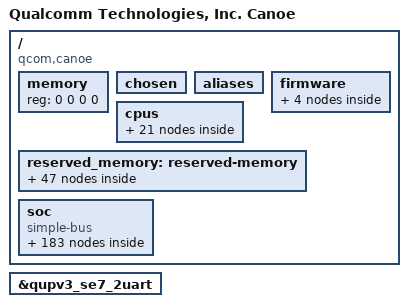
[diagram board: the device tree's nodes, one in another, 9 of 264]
// SPDX-License-Identifier: BSD-3-Clause
/*
 * Copyright (c) 2024 Qualcomm Innovation Center, Inc. All rights reserved.
 */

#include <dt-bindings/clock/qcom,rpmh.h>
#include <dt-bindings/clock/qcom,cambistmclkcc-canoe.h>
#include <dt-bindings/clock/qcom,camcc-canoe.h>
#include <dt-bindings/clock/qcom,evacc-canoe.h>
#include <dt-bindings/clock/qcom,gcc-canoe.h>
#include <dt-bindings/clock/qcom,gpucc-canoe.h>
#include <dt-bindings/clock/qcom,tcsrcc-canoe.h>
#include <dt-bindings/clock/qcom,videocc-canoe.h>
#include <dt-bindings/interrupt-controller/arm-gic.h>
#include <dt-bindings/interconnect/qcom,canoe.h>
#include <dt-bindings/interconnect/qcom,icc.h>
#include <dt-bindings/regulator/qcom,rpmh-regulator-levels.h>
#include <dt-bindings/soc/qcom,rpmh-rsc.h>
#include <dt-bindings/soc/qcom,ipcc.h>
#include <dt-bindings/spmi/spmi.h>
#include <dt-bindings/mailbox/qcom-ipcc-canoe.h>

/ {
	model = "Qualcomm Technologies, Inc. Canoe";
	compatible = "qcom,canoe";
	qcom,msm-id = <0x10294 0x10000>;
	interrupt-parent = <&intc>;

	#address-cells = <2>;
	#size-cells = <2>;
	memory { device_type = "memory"; reg = <0 0 0 0>; };


	chosen: chosen {
		bootargs = "nokaslr kpti=0 log_buf_len=256K swiotlb=0 loop.max_part=7";
		stdout-path = "/soc/qcom,qupv3_1_geni_se@ac0000/qcom,qup_uart@a9c000:115200n8";
	};

	aliases {
		serial0 = &qupv3_se7_2uart;
		hsuart0 = &qupv3_se18_4uart;
		ufshc1 = &ufshc_mem; /* Embedded UFS Slot */
		i2c0 = &qupv3_se0_i2c;
		i2c1 = &qupv3_se1_i2c;
		i2c2 = &qupv3_se2_i2c;
		i2c3 = &qupv3_se3_i2c;
		i2c4 = &qupv3_se4_i2c;
		i2c5 = &qupv3_se5_i2c;
		i2c6 = &qupv3_se6_i2c;
		i2c8 = &qupv3_se8_i2c;
		i2c9 = &qupv3_se9_i2c;
		i2c10 = &qupv3_se10_i2c;
		i2c11 = &qupv3_se11_i2c;
		i2c12 = &qupv3_se12_i2c;
		i2c13 = &qupv3_se13_i2c;
		i2c14 = &qupv3_se14_i2c;
		i2c15 = &qupv3_se15_i2c;
		i2c16 = &qupv3_se16_i2c;
		i2c17 = &qupv3_se17_i2c;
		i2c19 = &qupv3_se19_i2c;
		i2c20 = &qupv3_se20_i2c;
		i2c21 = &qupv3_se21_i2c;
		i2c22 = &qupv3_se22_i2c;
		i2c23 = &qupv3_se23_i2c;
		spi0 = &qupv3_se0_spi;
		spi1 = &qupv3_se1_spi;
		spi2 = &qupv3_se2_spi;
		spi3 = &qupv3_se3_spi;
		spi4 = &qupv3_se4_spi;
		spi5 = &qupv3_se5_spi;
		spi6 = &qupv3_se6_spi;
		spi8 = &qupv3_se8_spi;
		spi9 = &qupv3_se9_spi;
		spi10 = &qupv3_se10_spi;
		spi11 = &qupv3_se11_spi;
		spi14 = &qupv3_se14_spi;
		spi15 = &qupv3_se15_spi;
		spi16 = &qupv3_se16_spi;
		spi17 = &qupv3_se17_spi;
		spi19 = &qupv3_se19_spi;
		spi20 = &qupv3_se20_spi;
		spi21 = &qupv3_se21_spi;
	};

	firmware: firmware {
		qcom_scm: qcom_scm { };
	};

	cpus {
		#address-cells = <2>;
		#size-cells = <0>;

		CPU0: cpu@0 {
			device_type = "cpu";
			compatible = "arm,armv8";
			reg = <0x0 0x0>;
			enable-method = "psci";
			next-level-cache = <&L2_0>;
			L2_0: l2-cache {
			      compatible = "cache";
			      cache-level = <2>;
			};
		};

		CPU1: cpu@100 {
			device_type = "cpu";
			compatible = "arm,armv8";
			reg = <0x0 0x100>;
			enable-method = "psci";
			next-level-cache = <&L2_0>;
		};

		CPU2: cpu@200 {
			device_type = "cpu";
			compatible = "arm,armv8";
			reg = <0x0 0x200>;
			enable-method = "psci";
			next-level-cache = <&L2_0>;
		};

		CPU3: cpu@300 {
			device_type = "cpu";
			compatible = "arm,armv8";
			reg = <0x0 0x300>;
			enable-method = "psci";
			next-level-cache = <&L2_0>;
		};

		CPU4: cpu@400 {
			device_type = "cpu";
			compatible = "arm,armv8";
			reg = <0x0 0x400>;
			enable-method = "psci";
			next-level-cache = <&L2_0>;
		};

		CPU5: cpu@500 {
			device_type = "cpu";
			compatible = "arm,armv8";
			reg = <0x0 0x500>;
			enable-method = "psci";
			next-level-cache = <&L2_0>;
		};

		CPU6: cpu@10000 {
			device_type = "cpu";
			compatible = "arm,armv8";
			reg = <0x0 0x10000>;
			enable-method = "psci";
			next-level-cache = <&L2_6>;
			L2_6: l2-cache {
			      compatible = "cache";
			      cache-level = <2>;
			};
		};

		CPU7: cpu@10100 {
			device_type = "cpu";
			compatible = "arm,armv8";
			reg = <0x0 0x10100>;
			enable-method = "psci";
			next-level-cache = <&L2_6>;
		};

		cpu-map {
			cluster0 {
				core0 {
					cpu = <&CPU0>;
				};

				core1 {
					cpu = <&CPU1>;
				};

				core2 {
					cpu = <&CPU2>;
				};

				core3 {
					cpu = <&CPU3>;
				};

				core4 {
					cpu = <&CPU4>;
				};

				core5 {
					cpu = <&CPU5>;
				};
			};

			cluster1 {
				core0 {
					cpu = <&CPU6>;
				};

				core1 {
					cpu = <&CPU7>;
				};
			};
		};
	};

	reserved_memory: reserved-memory { };

	soc: soc { };
};

&firmware {
	qcom_scm {
		compatible = "qcom,scm";
		qcom,dload-mode = <&tcsr 0x19000>;
	};

	qcom_smcinvoke {
		compatible = "qcom,smcinvoke";
	};

	qcom_mem_object {
		compatible = "qcom,mem-object";
	};

	qtee_shmbridge {
		compatible = "qcom,tee-shared-memory-bridge";
	};
};

&soc {
	#address-cells = <2>;
	#size-cells = <2>;
	ranges = <0 0 0 0 0x10 0>;
	compatible = "simple-bus";

	ipcc_mproc: qcom,ipcc@1106000 {
		compatible = "qcom,ipcc";
		reg = <0x0 0x1106000 0x0 0x1000>;
		interrupts = <GIC_SPI 246 IRQ_TYPE_LEVEL_HIGH>;
		interrupt-controller;
		#interrupt-cells = <3>;
		#mbox-cells = <2>;
	};

	pdc: interrupt-controller@b220000 {
		compatible = "qcom,canoe-pdc", "qcom,pdc";
		reg = <0x0 0xb220000 0x0 0x10000>, <0x0 0x179600f0 0x0 0xf4>;
		qcom,pdc-ranges = <0 745 38>, <40 785 11>, <51 527 4>,
				  <58 534 2>, <61 537 20>, <84 559 14>,
				  <98 609 32>, <130 717 12>, <142 251 5>,
				  <147 796 16>, <163 783 2>, <165 531 2>,
				  <167 536 1>, <168 557 2>, <170 415 1>,
				  <171 438 1>, <172 579 1>, <173 703 1>,
				  <174 708 1>, <175 714 1>, <176 68 1>,
				  <177 86 1>, <178 96 1>, <179 249 1>;
		#interrupt-cells = <2>;
		interrupt-parent = <&intc>;
		interrupt-controller;
	};

	tcsr_mutex_block: syscon@1f40000 {
		compatible = "syscon";
		reg = <0x0 0x1f40000 0x0 0x20000>;
	};

	tcsr: syscon@1fc0000 {
		compatible = "syscon";
		reg = <0x0 0x1fc0000 0x0 0x30000>;
	};

	tcsr_mutex: hwlock {
		compatible = "qcom,tcsr-mutex";
		syscon = <&tcsr_mutex_block 0 0x1000>;
		#hwlock-cells = <1>;
	};

	aoss_qmp: power-controller@c300000 {
		compatible = "qcom,aoss-qmp";
		reg = <0x0 0xc300000 0x0 0x400>;
		interrupt-parent = <&ipcc_mproc>;
		interrupts = <IPCC_MPROC_AOP
			      IPCC_MPROC_SIGNAL_GLINK_QMP
			      IRQ_TYPE_EDGE_RISING>;
		mboxes = <&ipcc_mproc IPCC_MPROC_AOP
			  IPCC_MPROC_SIGNAL_GLINK_QMP>;

		#power-domain-cells = <1>;
		#clock-cells = <0>;
	};

	qmp_tme: qcom,qmp-tme {
		compatible = "qcom,qmp-mbox";
		qcom,remote-pid = <14>;
		mboxes = <&ipcc_mproc IPCC_MPROC_TME
			  IPCC_MPROC_SIGNAL_GLINK_QMP>;
		mbox-names = "tme_qmp";
		interrupt-parent = <&ipcc_mproc>;
		interrupts = <IPCC_MPROC_TME
			      IPCC_MPROC_SIGNAL_GLINK_QMP
			      IRQ_TYPE_EDGE_RISING>;

		label = "tme";
		qcom,early-boot;
		priority = <0>;
		mbox-desc-offset = <0x0>;
		#mbox-cells = <1>;
	};

	qcom,smp2p-adsp {
		compatible = "qcom,smp2p";
		qcom,smem = <443>, <429>;
		interrupt-parent = <&ipcc_mproc>;
		interrupts = <IPCC_MPROC_LPASS IPCC_MPROC_SIGNAL_SMP2P
			      IRQ_TYPE_EDGE_RISING>;
		mboxes = <&ipcc_mproc IPCC_MPROC_LPASS
			  IPCC_MPROC_SIGNAL_SMP2P>;
		qcom,local-pid = <0>;
		qcom,remote-pid = <2>;

		adsp_smp2p_out: master-kernel {
			qcom,entry-name = "master-kernel";
			#qcom,smem-state-cells = <1>;
		};

		adsp_smp2p_in: slave-kernel {
			qcom,entry-name = "slave-kernel";
			interrupt-controller;
			#interrupt-cells = <2>;
		};

		sleepstate_smp2p_out: sleepstate-out {
			qcom,entry-name = "sleepstate";
			#qcom,smem-state-cells = <1>;
		};

		sleepstate_smp2p_in: qcom,sleepstate-in {
			qcom,entry-name = "sleepstate_see";
			interrupt-controller;
			#interrupt-cells = <2>;
		};

		smp2p_rdbg2_out: qcom,smp2p-rdbg2-out {
			qcom,entry-name = "rdbg";
			#qcom,smem-state-cells = <1>;
		};

		smp2p_rdbg2_in: qcom,smp2p-rdbg2-in {
			qcom,entry-name = "rdbg";
			interrupt-controller;
			#interrupt-cells = <2>;
		};
	};

	qcom,smp2p-cdsp {
		compatible = "qcom,smp2p";
		qcom,smem = <94>, <432>;
		interrupt-parent = <&ipcc_mproc>;
		interrupts = <IPCC_MPROC_CDSP IPCC_MPROC_SIGNAL_SMP2P
			      IRQ_TYPE_EDGE_RISING>;
		mboxes = <&ipcc_mproc IPCC_MPROC_CDSP IPCC_MPROC_SIGNAL_SMP2P>;
		qcom,local-pid = <0>;
		qcom,remote-pid = <5>;

		cdsp_smp2p_out: master-kernel {
			qcom,entry-name = "master-kernel";
			#qcom,smem-state-cells = <1>;
		};

		cdsp_smp2p_in: slave-kernel {
			qcom,entry-name = "slave-kernel";
			interrupt-controller;
			#interrupt-cells = <2>;
		};

		smp2p_rdbg5_out: qcom,smp2p-rdbg5-out {
			qcom,entry-name = "rdbg";
			#qcom,smem-state-cells = <1>;
		};

		smp2p_rdbg5_in: qcom,smp2p-rdbg5-in {
			qcom,entry-name = "rdbg";
			interrupt-controller;
			#interrupt-cells = <2>;
		};
	};

	qcom,smp2p-modem {
		compatible = "qcom,smp2p";
		qcom,smem = <435>, <428>;
		interrupt-parent = <&ipcc_mproc>;
		interrupts = <IPCC_MPROC_MPSS IPCC_MPROC_SIGNAL_SMP2P
			      IRQ_TYPE_EDGE_RISING>;
		mboxes = <&ipcc_mproc IPCC_MPROC_MPSS IPCC_MPROC_SIGNAL_SMP2P>;
		qcom,local-pid = <0>;
		qcom,remote-pid = <1>;

		modem_smp2p_out: master-kernel {
			qcom,entry-name = "master-kernel";
			#qcom,smem-state-cells = <1>;
		};

		modem_smp2p_in: slave-kernel {
			qcom,entry-name = "slave-kernel";
			interrupt-controller;
			#interrupt-cells = <2>;
		};

		smp2p_ipa_1_out: qcom,smp2p-ipa-1-out {
			qcom,entry-name = "ipa";
			#qcom,smem-state-cells = <1>;
		};

		/* ipa - inbound entry from mss */
		smp2p_ipa_1_in: qcom,smp2p-ipa-1-in {
			qcom,entry-name = "ipa";
			interrupt-controller;
			#interrupt-cells = <2>;
		};

		smp2p_smem_mailbox_1_out: qcom,smp2p-smem-mailbox-1-out {
			qcom,entry-name = "smem-mailbox";
			#qcom,smem-state-cells = <1>;
		};

		smp2p_smem_mailbox_1_in: qcom,smp2p-smem-mailbox-1-in {
			qcom,entry-name = "smem-mailbox";
			interrupt-controller;
			#interrupt-cells = <2>;
		};
	};

	qcom,smp2p-soccp {
		compatible = "qcom,smp2p";
		qcom,smem = <617>, <616>;
		interrupt-parent = <&ipcc_mproc>;
		interrupts = <IPCC_MPROC_SOCCP IPCC_MPROC_SIGNAL_SMP2P
			      IRQ_TYPE_EDGE_RISING>;
		mboxes = <&ipcc_mproc IPCC_MPROC_SOCCP IPCC_MPROC_SIGNAL_SMP2P>;
		qcom,local-pid = <0>;
		qcom,remote-pid = <19>;

		soccp_smp2p_out: master-kernel {
			qcom,entry-name = "master-kernel";
			#qcom,smem-state-cells = <1>;
		};

		soccp_smp2p_in: slave-kernel {
			qcom,entry-name = "slave-kernel";
			interrupt-controller;
			#interrupt-cells = <2>;
		};
	};

	qcom,smp2p_sleepstate {
		compatible = "qcom,smp2p-sleepstate";
		qcom,smem-states = <&sleepstate_smp2p_out 0>;
		interrupt-parent = <&sleepstate_smp2p_in>;
		interrupts = <0 0>;
		interrupt-names = "smp2p-sleepstate-in";
	};

	tlmm: pinctrl@f000000 {
		compatible = "qcom,canoe-tlmm";
		reg = <0x0 0xf000000 0x0 0x1000000>;
		interrupts = <GIC_SPI 208 IRQ_TYPE_LEVEL_HIGH>;
		gpio-controller;
		#gpio-cells = <2>;
		interrupt-controller;
		#interrupt-cells = <2>;
		wakeup-parent = <&pdc>;
	};

	slimbam: bamdma@6C04000 {
		compatible = "qcom,bam-v1.7.0";
		qcom,controlled-remotely;
		reg = <0x6C04000 0x20000>, <0x6C8F000 0x1000>;
		reg-names = "bam", "bam_remote_mem";
		num-channels  = <31>;
		interrupts = <0 164 IRQ_TYPE_LEVEL_HIGH>;
		#dma-cells = <1>;
		qcom,ee = <1>;
		qcom,num-ees = <2>;
	};

	slim_msm: slim@6C40000 {
		compatible = "qcom,slim-ngd-v1.5.0";
		reg = <0x6C40000 0x2C000>, <0x6C8E000 0x1000>;
		reg-names = "ctrl", "slimbus_remote_mem";
		interrupts = <0 163 IRQ_TYPE_LEVEL_HIGH>;
		dmas = <&slimbam 3>, <&slimbam 4>;
		dma-names = "rx", "tx";
		#address-cells = <1>;
		#size-cells = <0>;
		status = "disabled";
	};

	intc: interrupt-controller@17000000 {
		compatible = "arm,gic-v3";
		#interrupt-cells = <3>;
		interrupt-controller;
		#redistributor-regions = <1>;
		redistributor-stride = <0x0 0x40000>;
		reg = <0x0 0x17000000 0x0 0x10000>,	/* GICD */
		      <0x0 0x17080000 0x0 0x200000>;	/* GICR * 8 */
		interrupts = <GIC_PPI 9 IRQ_TYPE_LEVEL_HIGH>;
	};

	memtimer: timer@17810000 {
		#address-cells = <1>;
		#size-cells = <1>;
		ranges;
		compatible = "arm,armv7-timer-mem";
		reg = <0x0 0x17810000 0x0 0x1000>;
		clock-frequency = <19200000>;

		frame@17811000 {
			frame-number = <0>;
			interrupts = <GIC_SPI 8 IRQ_TYPE_LEVEL_HIGH>,
				     <GIC_SPI 6 IRQ_TYPE_LEVEL_HIGH>;
			reg = <0x17811000 0x1000>,
			      <0x17812000 0x1000>;
		};

		frame@17813000 {
			frame-number = <1>;
			interrupts = <GIC_SPI 9 IRQ_TYPE_LEVEL_HIGH>;
			reg = <0x17813000 0x1000>;
			status = "disabled";
		};

		frame@17815000 {
			frame-number = <2>;
			interrupts = <GIC_SPI 10 IRQ_TYPE_LEVEL_HIGH>;
			reg = <0x17815000 0x1000>;
			status = "disabled";
		};

		frame@17817000 {
			frame-number = <3>;
			interrupts = <GIC_SPI 11 IRQ_TYPE_LEVEL_HIGH>;
			reg = <0x17817000 0x1000>;
			status = "disabled";
		};

		frame@17819000 {
			frame-number = <4>;
			interrupts = <GIC_SPI 12 IRQ_TYPE_LEVEL_HIGH>;
			reg = <0x17819000 0x1000>;
			status = "disabled";
		};

		frame@1781b000 {
			frame-number = <5>;
			interrupts = <GIC_SPI 13 IRQ_TYPE_LEVEL_HIGH>;
			reg = <0x1781b000 0x1000>;
			status = "disabled";
		};

		frame@1781d000 {
			frame-number = <6>;
			interrupts = <GIC_SPI 14 IRQ_TYPE_LEVEL_HIGH>;
			reg = <0x1781d000 0x1000>;
			status = "disabled";
		};
	};

	qcom_tzlog: tz-log@0 {
	};

	eud: qcom,msm-eud@88e0000 {
		compatible = "qcom,msm-eud";
		interrupt-names = "eud_irq";
		interrupt-parent = <&pdc>;
		interrupts = <11 IRQ_TYPE_LEVEL_HIGH>;
		reg = <0x0 0x88e0000 0x0 0x2000>,
				<0x0 0x88e2000 0x0 0x1000>;
		reg-names = "eud_base", "eud_mode_mgr2";
		qcom,secure-eud-en;
		qcom,eud-utmi-delay = /bits/ 16 <255>;
		status = "disabled";
	};

	cache-controller@31800000 {
		compatible = "qcom,canoe-llcc";
		reg = <0x0 0x31800000 0x0 0x200000>, <0x0 0x32800000 0x0 0x200000>,
			<0x0 0x31C00000 0x0 0x200000>, <0x0 0x32C00000 0x0 0x200000>,
			<0x0 0x34800000 0x0 0x200000>, <0x0 0x34C00000 0x0 0x200000>;
		reg-names = "llcc0_base", "llcc1_base", "llcc2_base",
			"llcc3_base", "llcc_broadcast_or_base",
			"llcc_broadcast_and_base";
		interrupts = <GIC_SPI 266 IRQ_TYPE_LEVEL_HIGH>;
		cap-based-alloc-and-pwr-collapse;
	};

	arch_timer: timer {
		compatible = "arm,armv8-timer";
		interrupts = <GIC_PPI 13 (GIC_CPU_MASK_SIMPLE(8) | IRQ_TYPE_LEVEL_LOW)>,
			     <GIC_PPI 14 (GIC_CPU_MASK_SIMPLE(8) | IRQ_TYPE_LEVEL_LOW)>,
			     <GIC_PPI 11 (GIC_CPU_MASK_SIMPLE(8) | IRQ_TYPE_LEVEL_LOW)>,
			     <GIC_PPI 10 (GIC_CPU_MASK_SIMPLE(8) | IRQ_TYPE_LEVEL_LOW)>;
		clock-frequency = <19200000>;
	};

	apps_rsc: rsc@18900000 {
		label = "apps_rsc";
		compatible = "qcom,rpmh-rsc";
		reg = <0x0 0x18900000 0x0 0x10000>,
		      <0x0 0x18910000 0x0 0x10000>,
		      <0x0 0x18920000 0x0 0x10000>;
		reg-names = "drv-0", "drv-1", "drv-2";
		qcom,drv-count = <3>;
		interrupts = <GIC_SPI 3 IRQ_TYPE_LEVEL_HIGH>,
			     <GIC_SPI 4 IRQ_TYPE_LEVEL_HIGH>,
			     <GIC_SPI 5 IRQ_TYPE_LEVEL_HIGH>;

		apps_rsc_drv2: drv@2 {
			qcom,drv-id = <2>;
			qcom,tcs-offset = <0xd00>;
			qcom,tcs-distance = <0x2a0>;
			channel@0 {
				qcom,tcs-config = <ACTIVE_TCS    3>,
						  <SLEEP_TCS     2>,
						  <WAKE_TCS      2>,
						  <CONTROL_TCS   0>,
						  <FAST_PATH_TCS 1>;
			};
		};
	};

	cam_rsc: rsc@9545000 {
		label = "cam_rsc";
		compatible = "qcom,rpmh-rsc";
		reg = <0x0 0x9545000 0x0 0x1000>,
		      <0x0 0x9546000 0x0 0x1000>,
		      <0x0 0x9547000 0x0 0x1000>;
		reg-names = "drv-0", "drv-1", "drv-2";
		qcom,drv-count = <3>;
		qcom,hw-channel;
		interrupts = <GIC_SPI 368 IRQ_TYPE_LEVEL_HIGH>,
			     <GIC_SPI 369 IRQ_TYPE_LEVEL_HIGH>,
			     <GIC_SPI 370 IRQ_TYPE_LEVEL_HIGH>;
		clocks = <&camcc CAM_CC_DRV_AHB_CLK>;

		cam_rsc_drv0: drv@0 {
			qcom,drv-id = <0>;
			qcom,tcs-offset = <0x520>;
			qcom,tcs-distance = <0x150>;
			channel@0 {
				qcom,tcs-config = <ACTIVE_TCS    0>,
						  <WAKE_TCS      1>,
						  <SLEEP_TCS     1>,
						  <CONTROL_TCS   0>,
						  <FAST_PATH_TCS 0>;
			};

			channel@1 {
				qcom,tcs-config = <ACTIVE_TCS    0>,
						  <WAKE_TCS      1>,
						  <SLEEP_TCS     1>,
						  <CONTROL_TCS   0>,
						  <FAST_PATH_TCS 0>;
			};
		};

		cam_rsc_drv1: drv@1 {
			qcom,drv-id = <1>;
			qcom,tcs-offset = <0x520>;
			qcom,tcs-distance = <0x150>;
			channel@0 {
				qcom,tcs-config = <ACTIVE_TCS    0>,
						  <WAKE_TCS      1>,
						  <SLEEP_TCS     1>,
						  <CONTROL_TCS   0>,
						  <FAST_PATH_TCS 0>;
			};

			channel@1 {
				qcom,tcs-config = <ACTIVE_TCS    0>,
						  <WAKE_TCS      1>,
						  <SLEEP_TCS     1>,
						  <CONTROL_TCS   0>,
						  <FAST_PATH_TCS 0>;
			};
		};

		cam_rsc_drv2: drv@2 {
			qcom,drv-id = <2>;
			qcom,tcs-offset = <0x520>;
			qcom,tcs-distance = <0x150>;
			channel@0 {
				qcom,tcs-config = <ACTIVE_TCS    0>,
						  <WAKE_TCS      1>,
						  <SLEEP_TCS     1>,
						  <CONTROL_TCS   0>,
						  <FAST_PATH_TCS 0>;
			};

			channel@1 {
				qcom,tcs-config = <ACTIVE_TCS    0>,
						  <WAKE_TCS      1>,
						  <SLEEP_TCS     1>,
						  <CONTROL_TCS   0>,
						  <FAST_PATH_TCS 0>;
			};
		};
	};

	disp_crm: crm@9bc3000 {
		label = "disp_crm";
		compatible = "qcom,disp-crm-v3";
		reg = <0x0 0x9bc3000 0x0 0x9000>, <0x0 0x9bcc000 0x0 0x400>, <0x0 0x9bcc400 0x0 0x400>,
		      <0x0 0x9bcc800 0x0 0x2000>, <0x0 0x9bce800 0x0 0x600>, <0x0 0x9bcee00 0x0 0x200>;
		reg-names = "base", "crm_b", "crm_b_pt", "crm_c", "crm_v", "common";
		interrupts = <GIC_SPI 812 IRQ_TYPE_EDGE_RISING>,
			     <GIC_SPI 813 IRQ_TYPE_EDGE_RISING>,
			     <GIC_SPI 814 IRQ_TYPE_EDGE_RISING>,
			     <GIC_SPI 815 IRQ_TYPE_EDGE_RISING>,
			     <GIC_SPI 816 IRQ_TYPE_EDGE_RISING>,
			     <GIC_SPI 817 IRQ_TYPE_EDGE_RISING>;
		interrupt-names = "disp_crm_drv0",
				  "disp_crm_drv1",
				  "disp_crm_drv2",
				  "disp_crm_drv3",
				  "disp_crm_drv4",
				  "disp_crm_drv5";
		qcom,hw-drv-ids = <0 1 2 3 4 5>;
		qcom,sw-drv-ids = <0 1 2 3 4 5>;
	};

	cam_crm: crm@9548000 {
		label = "cam_crm";
		compatible = "qcom,cam-crm-v3";
		reg = <0x0 0x9548000 0x0 0x1e00>, <0x0 0x9549e00 0x0 0x400>, <0x0 0x954a200 0x0 0x400>,
		      <0x0 0x954a600 0x0 0x2000>, <0x0 0x954c600 0x0 0x600>, <0x0 0x954cc00 0x0 0x200>;
		reg-names = "base", "crm_b", "crm_b_pt", "crm_c", "crm_v", "common";
		interrupts = <GIC_SPI 121 IRQ_TYPE_EDGE_RISING>;
		interrupt-names = "cam_crm_drv0";
		clocks = <&camcc CAM_CC_DRV_AHB_CLK>;
		qcom,hw-drv-ids = <0 1 2>;
		qcom,sw-drv-ids = <0>;
	};

	pcie_crm: crm@1d01000 {
		label = "pcie_crm";
		compatible = "qcom,pcie-crm-v3";
		reg = <0x0 0x1d01000 0x0 0x2000>, <0x0 0x1d03000 0x0 0x400>, <0x0 0x1d03400 0x0 0x400>,
		      <0x0 0x1d03800 0x0 0x2000>, <0x0 0x1d05800 0x0 0x600>, <0x0 0x1d05e00 0x0 0x200>;
		reg-names = "base", "crm_b", "crm_b_pt", "crm_c", "crm_v", "common";
		interrupts = <GIC_SPI 641 IRQ_TYPE_EDGE_RISING>;
		interrupt-names = "pcie_crm_drv0";
		clocks = <&pcie_0_pipe_clk>;
		qcom,hw-drv-ids = <0 1>;
		qcom,sw-drv-ids = <0>;
	};

	pcie_pdc: pdc@b370000 {
		compatible = "qcom,canoe-pcie-pdc", "qcom,pcie-pdc";
		reg = <0x0 0xb370000 0x0 0x10000>;
	};

	qcom,msm-imem@14680000 {
		compatible = "qcom,msm-imem";
		reg = <0x14680000 0x1000>;
		ranges = <0x0 0x14680000 0x1000>;
		#address-cells = <1>;
		#size-cells = <1>;

		mem_dump_table@10 {
			compatible = "qcom,msm-imem-mem_dump_table";
			reg = <0x10 0x8>;
		};

		restart_reason@65c {
			compatible = "qcom,msm-imem-restart_reason";
			reg = <0x65c 0x4>;
		};

		dload_type@1c {
			compatible = "qcom,msm-imem-dload-type";
			reg = <0x1c 0x4>;
		};

		boot_stats@6b0 {
			compatible = "qcom,msm-imem-boot_stats";
			reg = <0x6b0 0x20>;
		};

		kaslr_offset@6d0 {
			compatible = "qcom,msm-imem-kaslr_offset";
			reg = <0x6d0 0xc>;
		};

		pil@94c {
			compatible = "qcom,pil-reloc-info";
			reg = <0x94c 0xc8>;
		};

		pil@6dc {
			compatible = "qcom,msm-imem-pil-disable-timeout";
			reg = <0x6dc 0x4>;
		};

		diag_dload@c8 {
			compatible = "qcom,msm-imem-diag-dload";
			reg = <0xc8 0xc8>;
		};

		modem_dsm@c98 {
			compatible = "qcom,msm-imem-mss-dsm";
			reg = <0xc98 0x10>;
		};

		sys_dbg@af8 {
			compatible = "qcom,msm-imem-gpu-dump-skip";
			reg = <0xb0c 0x4>;
		};
	};

	clocks {
		xo_board: xo_board {
			compatible = "fixed-clock";
			clock-frequency = <76800000>;
			clock-output-names = "xo_board";
			#clock-cells = <0>;
		};

		sleep_clk: sleep_clk {
			compatible = "fixed-clock";
			clock-frequency = <32000>;
			clock-output-names = "sleep_clk";
			#clock-cells = <0>;
		};

		pcie_0_pipe_clk: pcie_0_pipe_clk {
			compatible = "fixed-clock";
			clock-frequency = <1000>;
			clock-output-names = "pcie_0_pipe_clk";
			#clock-cells = <0>;
		};

		ufs_phy_rx_symbol_0_clk: ufs_phy_rx_symbol_0_clk {
			compatible = "fixed-clock";
			clock-frequency = <1000>;
			clock-output-names = "ufs_phy_rx_symbol_0_clk";
			#clock-cells = <0>;
		};

		ufs_phy_rx_symbol_1_clk: ufs_phy_rx_symbol_1_clk {
			compatible = "fixed-clock";
			clock-frequency = <1000>;
			clock-output-names = "ufs_phy_rx_symbol_1_clk";
			#clock-cells = <0>;
		};

		ufs_phy_tx_symbol_0_clk: ufs_phy_tx_symbol_0_clk {
			compatible = "fixed-clock";
			clock-frequency = <1000>;
			clock-output-names = "ufs_phy_tx_symbol_0_clk";
			#clock-cells = <0>;
		};

		usb3_phy_wrapper_gcc_usb30_pipe_clk: usb3_phy_wrapper_gcc_usb30_pipe_clk {
			compatible = "fixed-clock";
			clock-frequency = <1000>;
			clock-output-names = "usb3_phy_wrapper_gcc_usb30_pipe_clk";
			#clock-cells = <0>;
		};
	};

	cxo: bi_tcxo {
		compatible = "fixed-factor-clock";
		clocks = <&xo_board>;
		clock-mult = <1>;
		clock-div = <4>;
		#clock-cells = <0>;
		clock-output-names = "bi_tcxo";
	};

	cxo_a: bi_tcxo_ao {
		compatible = "fixed-factor-clock";
		clocks = <&xo_board>;
		clock-mult = <1>;
		clock-div = <4>;
		#clock-cells = <0>;
		clock-output-names = "bi_tcxo_ao";
	};

	rpmhcc: clock-controller {
		compatible = "fixed-clock";
		clock-output-names = "rpmh_clocks";
		clock-frequency = <19200000>;
		#clock-cells = <1>;
	};

	cambistmclkcc: clock-controller@1760000 {
		compatible = "qcom,dummycc";
		clock-output-names = "cambistmclkcc_clocks";
		#clock-cells = <1>;
		#reset-cells = <1>;
	};

	camcc_crm: syscon@954a600 {
		compatible = "syscon";
		reg = <0x0 0x954a600 0x0 0x2000>;
	};

	camcc: clock-controller@956d000 {
		compatible = "qcom,dummycc";
		clock-output-names = "camcc_clocks";
		#clock-cells = <1>;
		#reset-cells = <1>;
	};

	evacc: clock-controller@24f0000 {
		compatible = "qcom,dummycc";
		clock-output-names = "evacc_clocks";
		#clock-cells = <1>;
		#reset-cells = <1>;
	};


	gcc: clock-controller@100000 {
		compatible = "qcom,canoe-gcc", "syscon";
		reg = <0x0 0x100000 0x0 0x1f4200>;
		reg-name = "cc_base";
		vdd_cx-supply = <&VDD_CX_LEVEL>;
		vdd_mx-supply = <&VDD_MX_LEVEL>;
		clocks = <&rpmhcc RPMH_CXO_CLK>,
			 <&pcie_0_pipe_clk>,
			 <&sleep_clk>,
			 <&ufs_phy_rx_symbol_0_clk>,
			 <&ufs_phy_rx_symbol_1_clk>,
			 <&ufs_phy_tx_symbol_0_clk>,
			 <&usb3_phy_wrapper_gcc_usb30_pipe_clk>;
		clock-names = "bi_tcxo",
			      "pcie_0_pipe_clk",
			      "sleep_clk",
			      "ufs_phy_rx_symbol_0_clk",
			      "ufs_phy_rx_symbol_1_clk",
			      "ufs_phy_tx_symbol_0_clk",
			      "usb3_phy_wrapper_gcc_usb30_pipe_clk";
		#clock-cells = <1>;
		#reset-cells = <1>;
	};

	gpucc: clock-controller@3d90000 {
		compatible = "qcom,dummycc";
		clock-output-names = "gpucc_clocks";
		#clock-cells = <1>;
		#reset-cells = <1>;
	};

	tcsrcc: clock-controller@1fd5044 {
		compatible = "qcom,dummycc";
		clock-output-names = "tcsrcc_clocks";
		#clock-cells = <1>;
		#reset-cells = <1>;
	};

	videocc: clock-controller@20f0000 {
		compatible = "qcom,dummycc";
		clock-output-names = "videocc_clocks";
		#clock-cells = <1>;
		#reset-cells = <1>;
	};

	apsscc: syscon@17c00000 {
		compatible = "syscon";
		reg = <0x0 0x17c00000 0x0 0x2da3000>;
	};

	gxclkctl: syscon@3d64000 {
		compatible = "syscon";
		reg = <0x0 0x3d64000 0x0 0x5000>;
	};

	mccc: syscon@310ba000 {
		compatible = "syscon";
		reg = <0x0 0x310ba000 0x0 0x800>;
	};

	/* CAM_CC GDSCs */
	cam_cc_ipe_0_gdsc: qcom,gdsc@958d174 {
		compatible = "qcom,stub-regulator";
		regulator-name = "cam_cc_ipe_0_gdsc";
		qcom,support-hw-trigger;
		qcom,support-cfg-gdscr;
	};

	cam_cc_ofe_gdsc: qcom,gdsc@958d0c8 {
		compatible = "qcom,stub-regulator";
		regulator-name = "cam_cc_ofe_gdsc";
		qcom,support-hw-trigger;
		qcom,support-cfg-gdscr;
	};

	cam_cc_tfe_0_gdsc: qcom,gdsc@958e004 {
		compatible = "qcom,stub-regulator";
		regulator-name = "cam_cc_tfe_0_gdsc";
		qcom,support-cfg-gdscr;
	};

	cam_cc_tfe_1_gdsc: qcom,gdsc@958e080 {
		compatible = "qcom,stub-regulator";
		regulator-name = "cam_cc_tfe_1_gdsc";
		qcom,support-cfg-gdscr;
	};

	cam_cc_tfe_2_gdsc: qcom,gdsc@958e0e4 {
		compatible = "qcom,stub-regulator";
		regulator-name = "cam_cc_tfe_2_gdsc";
		qcom,support-cfg-gdscr;
	};

	cam_cc_titan_top_gdsc: qcom,gdsc@958e334 {
		compatible = "qcom,stub-regulator";
		regulator-name = "cam_cc_titan_top_gdsc";
		qcom,support-cfg-gdscr;
	};

	/* EVA_CC GDSCs */
	eva_cc_mvs0_gdsc: qcom,gdsc@24f8068 {
		compatible = "qcom,stub-regulator";
		regulator-name = "eva_cc_mvs0_gdsc";
		qcom,support-hw-trigger;
		qcom,support-cfg-gdscr;
	};

	eva_cc_mvs0c_gdsc: qcom,gdsc@24f8034 {
		compatible = "qcom,stub-regulator";
		regulator-name = "eva_cc_mvs0c_gdsc";
		qcom,support-cfg-gdscr;
	};

	gcc_apcs_gdsc_vote_ctrl: syscon@15214c {
		compatible = "syscon";
		reg = <0x0 0x15214c 0x0 0x4>;
	};

	/* GCC GDSCs */
	gcc_pcie_0_gdsc: qcom,gdsc@16b004 {
		compatible = "qcom,gdsc";
		reg = <0x0 0x16b004 0x0 0x4>;
		regulator-name = "gcc_pcie_0_gdsc";
		parent-supply = <&VDD_CX_LEVEL>;
		qcom,retain-regs;
		qcom,no-status-check-on-disable;
		qcom,collapse-vote = <&gcc_apcs_gdsc_vote_ctrl 0>;
		qcom,support-cfg-gdscr;
	};

	gcc_pcie_0_phy_gdsc: qcom,gdsc@16c000 {
		compatible = "qcom,gdsc";
		reg = <0x0 0x16c000 0x0 0x4>;
		regulator-name = "gcc_pcie_0_phy_gdsc";
		parent-supply = <&VDD_MX_LEVEL>;
		qcom,retain-regs;
		qcom,no-status-check-on-disable;
		qcom,collapse-vote = <&gcc_apcs_gdsc_vote_ctrl 2>;
		qcom,support-cfg-gdscr;
	};

	gcc_ufs_mem_phy_gdsc: qcom,gdsc@19e000 {
		compatible = "qcom,gdsc";
		reg = <0x0 0x19e000 0x0 0x4>;
		regulator-name = "gcc_ufs_mem_phy_gdsc";
		parent-supply = <&VDD_MX_LEVEL>;
		proxy-supply = <&gcc_ufs_mem_phy_gdsc>;
		qcom,proxy-consumer-enable;
		qcom,retain-regs;
		qcom,support-cfg-gdscr;
	};

	gcc_ufs_phy_gdsc: qcom,gdsc@177004 {
		compatible = "qcom,gdsc";
		reg = <0x0 0x177004 0x0 0x4>;
		regulator-name = "gcc_ufs_phy_gdsc";
		parent-supply = <&VDD_CX_LEVEL>;
		proxy-supply = <&gcc_ufs_phy_gdsc>;
		qcom,proxy-consumer-enable;
		qcom,retain-regs;
		qcom,support-cfg-gdscr;
	};

	gcc_usb30_prim_gdsc: qcom,gdsc@139004 {
		compatible = "qcom,gdsc";
		reg = <0x0 0x139004 0x0 0x4>;
		regulator-name = "gcc_usb30_prim_gdsc";
		proxy-supply = <&gcc_usb30_prim_gdsc>;
		qcom,proxy-consumer-enable;
		qcom,retain-regs;
		qcom,support-cfg-gdscr;
	};

	gcc_usb3_phy_gdsc: qcom,gdsc@150018 {
		compatible = "qcom,gdsc";
		reg = <0x0 0x150018 0x0 0x4>;
		regulator-name = "gcc_usb3_phy_gdsc";
		parent-supply = <&VDD_MX_LEVEL>;
		proxy-supply = <&gcc_usb3_phy_gdsc>;
		qcom,proxy-consumer-enable;
		qcom,retain-regs;
		qcom,support-cfg-gdscr;
	};

	/* GPU_CC GDSCs */
	gpu_cc_cx_gdsc_hw_ctrl: syscon@3d99094 {
		compatible = "syscon";
		reg = <0x0 0x3d99094 0x0 0x4>;
	};

	gpu_cc_cx_gdsc: qcom,gdsc@3d99080 {
		compatible = "qcom,stub-regulator";
		regulator-name = "gpu_cc_cx_gdsc";
		qcom,support-cfg-gdscr;
	};

	/* VIDEO_CC GDSCs */
	video_cc_mvs0_gdsc: qcom,gdsc@20f80a8 {
		compatible = "qcom,stub-regulator";
		regulator-name = "video_cc_mvs0_gdsc";
		qcom,support-hw-trigger;
		qcom,support-cfg-gdscr;
	};

	video_cc_mvs0_vpp0_gdsc: qcom,gdsc@20f8120 {
		compatible = "qcom,stub-regulator";
		regulator-name = "video_cc_mvs0_vpp0_gdsc";
		qcom,support-hw-trigger;
		qcom,support-cfg-gdscr;
	};

	video_cc_mvs0_vpp1_gdsc: qcom,gdsc@20f80f4 {
		compatible = "qcom,stub-regulator";
		regulator-name = "video_cc_mvs0_vpp1_gdsc";
		qcom,support-hw-trigger;
		qcom,support-cfg-gdscr;
	};

	video_cc_mvs0a_gdsc: qcom,gdsc@20f807c {
		compatible = "qcom,stub-regulator";
		regulator-name = "video_cc_mvs0a_gdsc";
		qcom,support-hw-trigger;
		qcom,support-cfg-gdscr;
	};

	video_cc_mvs0c_gdsc: qcom,gdsc@20f814c {
		compatible = "qcom,stub-regulator";
		regulator-name = "video_cc_mvs0c_gdsc";
		qcom,support-cfg-gdscr;
	};

	clk_virt: interconnect@0 {
		compatible = "qcom,canoe-clk_virt";
		qcom,stub;
		#interconnect-cells = <1>;
	};

	mc_virt: interconnect@1 {
		compatible = "qcom,canoe-mc_virt";
		qcom,stub;
		#interconnect-cells = <1>;
	};

	config_noc: interconnect@1600000 {
		compatible = "qcom,canoe-cnoc_cfg";
		qcom,stub;
		#interconnect-cells = <1>;
	};

	cnoc_main: interconnect@1500000 {
		compatible = "qcom,canoe-cnoc_main";
		qcom,stub;
		#interconnect-cells = <1>;
	};

	system_noc: interconnect@1680000 {
		compatible = "qcom,canoe-system_noc";
		qcom,stub;
		#interconnect-cells = <1>;
	};

	pcie_noc: interconnect@16c0000 {
		compatible = "qcom,canoe-pcie_anoc";
		qcom,stub;
		#interconnect-cells = <1>;
	};

	aggre1_noc: interconnect@16e0000 {
		compatible = "qcom,canoe-aggre1_noc";
		qcom,stub;
		#interconnect-cells = <1>;
	};

	aggre2_noc: interconnect@1700000 {
		compatible = "qcom,canoe-aggre2_noc";
		qcom,stub;
		#interconnect-cells = <1>;
	};

	mmss_noc: interconnect@1780000 {
		compatible = "qcom,canoe-mmss_noc";
		qcom,stub;
		#interconnect-cells = <1>;
	};

	gem_noc: interconnect@31100000 {
		compatible = "qcom,canoe-gem_noc";
		qcom,stub;
		#interconnect-cells = <1>;
	};

	nsp_noc: interconnect@260c0000 {
		compatible = "qcom,canoe-nsp_noc";
		qcom,stub;
		#interconnect-cells = <1>;
	};

	lpass_ag_noc: interconnect@7f40000 {
		compatible = "qcom,canoe-lpass_ag_noc";
		qcom,stub;
		#interconnect-cells = <1>;
	};

	lpass_lpiaon_noc: interconnect@7400000 {
		compatible = "qcom,canoe-lpass_lpiaon_noc";
		qcom,stub;
		#interconnect-cells = <1>;
	};

	lpass_lpicx_noc: interconnect@7420000 {
		compatible = "qcom,canoe-lpass_lpicx_noc";
		qcom,stub;
		#interconnect-cells = <1>;
	};

	pmic_arbiter: arbiter@c400000 {
		compatible = "qcom,canoe-spmi-pmic-arb";
		reg = <0x0 0xc400000 0x0 0x3000>,
		      <0x0 0xc900000 0x0 0x400000>,
		      <0x0 0xc4c0000 0x0 0x400000>,
		      <0x0 0xc403000 0x0 0x8000>;
		reg-names = "core", "chnls", "obsrvr", "chnl_map";
		#address-cells = <2>;
		#size-cells = <2>;
		ranges;
		qcom,channel = <0>;
		qcom,ee = <0>;

		spmi0_bus: spmi@c426000 {
			reg = <0x0 0xc426000 0x0 0x4000>,
			      <0x0 0xc8c0000 0x0 0x10000>,
			      <0x0 0xc42a000 0x0 0x8000>;
			reg-names = "cnfg", "intr", "chnl_owner";
			interrupts-extended = <&pdc 1 IRQ_TYPE_LEVEL_HIGH>;
			interrupt-names = "periph_irq";
			interrupt-controller;
			#interrupt-cells = <4>;
			#address-cells = <2>;
			#size-cells = <0>;
		};

		spmi1_bus: spmi@c437000 {
			reg = <0x0 0xc437000 0x0 0x4000>,
			      <0x0 0xc8d0000 0x0 0x10000>,
			      <0x0 0xc43b000 0x0 0x8000>;
			reg-names = "cnfg", "intr", "chnl_owner";
			interrupts-extended = <&pdc 3 IRQ_TYPE_LEVEL_HIGH>;
			interrupt-names = "periph_irq";
			interrupt-controller;
			#interrupt-cells = <4>;
			#address-cells = <2>;
			#size-cells = <0>;
		};
	};

	pmic-arb-debug@11314000 {
		compatible = "qcom,spmi-pmic-arb-debug-v8";
		reg = <0x0 0x11314000 0x0 0x64>,
		      <0x0 0x221c8780 0x0 0x4>;
		reg-names = "core", "fuse";
		clocks = <&aoss_qmp>;
		clock-names = "core_clk";
		qcom,fuse-enable-bit = <14>;
		#address-cells = <1>;
		#size-cells = <0>;
		depends-on-supply = <&pmic_arbiter>;

		spmi_debug_bus_0: spmi@0 {
			reg = <0>;
			#address-cells = <2>;
			#size-cells = <0>;

			pmk8850@0 {
				compatible = "qcom,spmi-pmic";
				reg = <0 SPMI_USID>;
				#address-cells = <2>;
				#size-cells = <0>;
				qcom,can-sleep;
			};

			pmh0101@1 {
				compatible = "qcom,spmi-pmic";
				reg = <1 SPMI_USID>;
				#address-cells = <2>;
				#size-cells = <0>;
				qcom,can-sleep;
			};

			pmh0110@3 {
				compatible = "qcom,spmi-pmic";
				reg = <3 SPMI_USID>;
				#address-cells = <2>;
				#size-cells = <0>;
				qcom,can-sleep;
			};

			pmh0110@5 {
				compatible = "qcom,spmi-pmic";
				reg = <5 SPMI_USID>;
				#address-cells = <2>;
				#size-cells = <0>;
				qcom,can-sleep;
			};

			pmh0110@6 {
				compatible = "qcom,spmi-pmic";
				reg = <6 SPMI_USID>;
				#address-cells = <2>;
				#size-cells = <0>;
				qcom,can-sleep;
			};

			pmh0110@8 {
				compatible = "qcom,spmi-pmic";
				reg = <8 SPMI_USID>;
				#address-cells = <2>;
				#size-cells = <0>;
				qcom,can-sleep;
			};
		};

		spmi_debug_bus_1: spmi@1 {
			reg = <1>;
			#address-cells = <2>;
			#size-cells = <0>;

			pmd802x@4 {
				compatible = "qcom,spmi-pmic";
				reg = <4 SPMI_USID>;
				#address-cells = <2>;
				#size-cells = <0>;
				qcom,can-sleep;
			};

			pmih010x@7 {
				compatible = "qcom,spmi-pmic";
				reg = <7 SPMI_USID>;
				#address-cells = <2>;
				#size-cells = <0>;
				qcom,can-sleep;
			};

			pmh0104@9 {
				compatible = "qcom,spmi-pmic";
				reg = <9 SPMI_USID>;
				#address-cells = <2>;
				#size-cells = <0>;
				qcom,can-sleep;
			};

			pmr735d@a {
				compatible = "qcom,spmi-pmic";
				reg = <10 SPMI_USID>;
				#address-cells = <2>;
				#size-cells = <0>;
				qcom,can-sleep;
			};

			pm8010@c {
				compatible = "qcom,spmi-pmic";
				reg = <12 SPMI_USID>;
				#address-cells = <2>;
				#size-cells = <0>;
				qcom,can-sleep;
			};

			pm8010@d {
				compatible = "qcom,spmi-pmic";
				reg = <13 SPMI_USID>;
				#address-cells = <2>;
				#size-cells = <0>;
				qcom,can-sleep;
			};
		};
	};

	ufsphy_mem: ufsphy_mem@1d80000 {
		reg = <0x0 0x1d80000 0x0 0x2000>;
		reg-names = "phy_mem";
		#phy-cells = <0>;

		lanes-per-direction = <2>;
		clock-names = "ref_clk_src",
			"ref_aux_clk", "qref_clk",
			"rx_sym0_mux_clk", "rx_sym1_mux_clk", "tx_sym0_mux_clk",
			"rx_sym0_phy_clk", "rx_sym1_phy_clk", "tx_sym0_phy_clk";
		clocks = <&rpmhcc RPMH_CXO_PAD_CLK>,
			<&gcc GCC_UFS_PHY_PHY_AUX_CLK>,
			<&tcsrcc TCSR_UFS_CLKREF_EN>,
			<&gcc GCC_UFS_PHY_RX_SYMBOL_0_CLK_SRC>,
			<&gcc GCC_UFS_PHY_RX_SYMBOL_1_CLK_SRC>,
			<&gcc GCC_UFS_PHY_TX_SYMBOL_0_CLK_SRC>,
			<&gcc GCC_UFS_PHY_RX_SYMBOL_0_CLK>,
			<&gcc GCC_UFS_PHY_RX_SYMBOL_1_CLK>,
			<&gcc GCC_UFS_PHY_TX_SYMBOL_0_CLK>;
		resets = <&ufshc_mem 0>;
		status = "disabled";
	};

	ice_cfg: shared_ice {
		 alg1 {
		      alg-name = "alg1";
		      rx-alloc-percent = <60>;
		      status = "disabled";
		 };

		 alg2 {
		      alg-name = "alg2";
		      status = "disabled";

		 };

		 alg3 {
		      alg-name = "alg3";
		      num-core = <28 28 15 13>;
		      status = "ok";
		 };
	};

	ufshc_dma_resv: ufshc_dma_resv_region {
		/*
		 * Restrict IOVA mappings for UFSHC buffers to the 3 GB region
		 * from 0x1000 - 0xffffffff.
		 */
		iommu-addresses = <&ufshc_mem 0x0 0x0 0x0 0x1000>;
	};

	adsp_pas: remoteproc-adsp@03000000 {
		compatible = "qcom,canoe-adsp-pas";
		reg = <0x03000000 0x10000>;
		status = "ok";

		cx-supply = <&VDD_LPI_CX_LEVEL>;
		cx-uV-uA = <RPMH_REGULATOR_LEVEL_TURBO 0>;
		mx-supply = <&VDD_LPI_MX_LEVEL>;
		mx-uV-uA = <RPMH_REGULATOR_LEVEL_TURBO 0>;
		reg-names = "cx", "mx";

		clocks = <&rpmhcc RPMH_CXO_CLK>;
		clock-names = "xo";

		qcom,qmp = <&aoss_qmp>;

		interconnects = <&lpass_lpicx_noc MASTER_LPASS_PROC &mc_virt SLAVE_EBI1>,
				<&aggre2_noc MASTER_CRYPTO &mc_virt SLAVE_EBI1>;
		interconnect-names = "rproc_ddr", "crypto_ddr";

		firmware-name = "adsp.mdt", "adsp_dtb.mdt";

		memory-region = <&adspslpi_mem &q6_adsp_dtb_mem>;

		/* Inputs from ssc */
		interrupts-extended = <&pdc 6 IRQ_TYPE_EDGE_RISING>,
					<&adsp_smp2p_in 0 0>,
					<&adsp_smp2p_in 2 0>,
					<&adsp_smp2p_in 1 0>,
					<&adsp_smp2p_in 3 0>;

		interrupt-names = "wdog",
				"fatal",
				"handover",
				"ready",
				"stop-ack";

		/* Outputs to turing */
		qcom,smem-states = <&adsp_smp2p_out 0>;
		qcom,smem-state-names = "stop";

		remoteproc_adsp_glink: glink-edge {
			qcom,remote-pid = <2>;
			transport = "smem";
			mboxes = <&ipcc_mproc IPCC_CLIENT_LPASS
				  IPCC_MPROC_SIGNAL_GLINK_QMP>;
			mbox-names = "adsp_smem";
			interrupt-parent = <&ipcc_mproc>;
			interrupts = <IPCC_CLIENT_LPASS
				      IPCC_MPROC_SIGNAL_GLINK_QMP
				      IRQ_TYPE_EDGE_RISING>;

			label = "adsp";
			qcom,glink-label = "lpass";

			qcom,adsp_qrtr {
				qcom,glink-channels = "IPCRTR";
				qcom,net-id = <2>;
				qcom,intents = <0x800  5
						0x2000 3
						0x4400 2>;

				qcom,no-wake-svc = <0x190>;
			};

			qcom,pmic_glink_rpmsg {
				qcom,glink-channels = "PMIC_RTR_ADSP_APPS";
			};

			qcom,pmic_glink_log_rpmsg {
				qcom,glink-channels = "PMIC_LOGS_ADSP_APPS";
				qcom,intents = <0x800 5
						0xc00 3
						0x2000 1>;
			};
		};
	};

	cdsp_pas: remoteproc-cdsp@32300000 {
		compatible = "qcom,canoe-cdsp-pas";
		reg = <0x32300000 0x10000>;
		status = "ok";

		cx-supply = <&VDD_CX_LEVEL>;
		cx-uV-uA = <RPMH_REGULATOR_LEVEL_TURBO 100000>;
		mx-supply = <&VDD_MXC_LEVEL>;
		mx-uV-uA = <RPMH_REGULATOR_LEVEL_TURBO 100000>;
		nsp-supply = <&VDD_NSP1_LEVEL>;
		nsp-uV-uA = <RPMH_REGULATOR_LEVEL_TURBO 100000>;
		reg-names = "cx","mx","nsp";

		firmware-name = "cdsp.mdt", "cdsp_dtb.mdt";
		memory-region = <&cdsp_mem &q6_cdsp_dtb_mem &global_sync_mem>;

		clocks = <&rpmhcc RPMH_CXO_CLK>;
		clock-names = "xo";

		qcom,qmp = <&aoss_qmp>;

		interconnects = <&nsp_noc MASTER_CDSP_PROC &mc_virt SLAVE_EBI1>,
				<&aggre2_noc MASTER_CRYPTO &mc_virt SLAVE_EBI1>;
		interconnect-names = "rproc_ddr", "crypto_ddr";

		/* Inputs from turing */
		interrupts-extended = <&intc GIC_SPI 578 IRQ_TYPE_EDGE_RISING>,
					<&cdsp_smp2p_in 0 0>,
					<&cdsp_smp2p_in 2 0>,
					<&cdsp_smp2p_in 1 0>,
					<&cdsp_smp2p_in 3 0>;

		interrupt-names = "wdog",
				"fatal",
				"handover",
				"ready",
				"stop-ack";

		/* Outputs to turing */
		qcom,smem-states = <&cdsp_smp2p_out 0>;
		qcom,smem-state-names = "stop";

		remoteproc_cdsp_glink: glink-edge {
			qcom,remote-pid = <5>;
			transport = "smem";
			mboxes = <&ipcc_mproc IPCC_CLIENT_CDSP
				  IPCC_MPROC_SIGNAL_GLINK_QMP>;
			mbox-names = "cdsp_smem";
			interrupt-parent = <&ipcc_mproc>;
			interrupts = <IPCC_CLIENT_CDSP
				      IPCC_MPROC_SIGNAL_GLINK_QMP
				      IRQ_TYPE_EDGE_RISING>;

			label = "cdsp";
			qcom,glink-label = "cdsp";

			qcom,cdsp_qrtr {
				qcom,glink-channels = "IPCRTR";
				qcom,intents = <0x800  5
						0x2000 3
						0x4400 2>;
			};

			qcom,msm_cdsprm_rpmsg {
				compatible = "qcom,msm-cdsprm-rpmsg";
				qcom,glink-channels = "cdsprmglink-apps-dsp";
				qcom,intents = <0x20 12
						0xF00 12>;

				msm_cdsp_rm: qcom,msm_cdsp_rm {
					compatible = "qcom,msm-cdsp-rm";
					qcom,qos-cores = <0 1>;
					qcom,qos-latency-us = <70>;
					qcom,qos-maxhold-ms = <20>;
				};
			};
		};
	};

	ufshc_mem: ufshc@1d84000 {
		compatible = "qcom,ufshc";
		reg = <0x0 0x1d84000 0x0 0x3000>,
		      <0x0 0x1d88000 0x0 0x18000>,
		      <0x0 0x1da5000 0x0 0x2000>,
		      <0x0 0x1da4000 0x0 0x10>;
		reg-names = "ufs_mem", "ice", "mcq_sqd", "mcq_vs";
		interrupts = <GIC_SPI 265 IRQ_TYPE_LEVEL_HIGH>;
		phys = <&ufsphy_mem>;
		phy-names = "ufsphy";
		#reset-cells = <1>;

// Remove for RUMI. Try to enable it later after the basic bootup works.
//		qcom,ice-use-hwkm;
//		qcom,prime-mask = <0xc0>;
//		qcom,silver-mask = <0x3f>;
//		qcom,esi-affinity-mask = <0xe0>;

		lanes-per-direction = <2>;
		dev-ref-clk-freq = <0>; /* 19.2 MHz */
		clock-names =
			"core_clk",
			"bus_aggr_clk",
			"iface_clk",
			"core_clk_unipro",
			"core_clk_ice",
			"ref_clk",
			"tx_lane0_sync_clk",
			"rx_lane0_sync_clk",
			"rx_lane1_sync_clk";
		clocks =
			<&gcc GCC_UFS_PHY_AXI_CLK>,
			<&gcc GCC_AGGRE_UFS_PHY_AXI_CLK>,
			<&gcc GCC_UFS_PHY_AHB_CLK>,
			<&gcc GCC_UFS_PHY_UNIPRO_CORE_CLK>,
			<&gcc GCC_UFS_PHY_ICE_CORE_CLK>,
			<&rpmhcc RPMH_LN_BB_CLK3>,
			<&gcc GCC_UFS_PHY_TX_SYMBOL_0_CLK>,
			<&gcc GCC_UFS_PHY_RX_SYMBOL_0_CLK>,
			<&gcc GCC_UFS_PHY_RX_SYMBOL_1_CLK>;
		freq-table-hz =
			<100000000 403000000>,
			<0 0>,
			<0 0>,
			<100000000 403000000>,
			<100000000 403000000>,
			<0 0>,
			<0 0>,
			<0 0>,
			<0 0>;

		interconnects = <&aggre1_noc MASTER_UFS_MEM &mc_virt SLAVE_EBI1>,
		      <&gem_noc MASTER_APPSS_PROC &config_noc SLAVE_UFS_MEM_CFG>;
		interconnect-names = "ufs-ddr", "cpu-ufs";

		iommus = <&apps_smmu 0x60 0x0>;
		qcom,iommu-dma = "fastmap";
		qcom,iommu-msi-size = <0x1000>;
		memory-region = <&ufshc_dma_resv>;
		shared-ice-cfg = <&ice_cfg>;
		dma-coherent;

		qcom,bypass-pbl-rst-wa;
		qcom,max-cpus = <8>;

// Remove because gic_its is not available
//		msi-parent = <&gic_its 0x60>;

		status = "disabled";

		qos0 {
			mask = <0xc0>;
			vote = <44>;
			perf;
			/* Set CPU6 to fmax, and CPU[6-7] will run at fmax */
			cpu_freq_vote = <6>;
		};

		qos1 {
			mask = <0x3f>;
			vote = <44>;
			/* Set CPU0 to fmax, and CPU[0-5] will run at fmax */
			cpu_freq_vote = <0>;
		};
	};

	cpu_pmu: cpu-pmu {
		compatible = "arm,armv8-pmuv3";
		interrupts = <GIC_PPI 7 IRQ_TYPE_LEVEL_HIGH>;
	};

	psci {
		compatible = "arm,psci-1.0";
		method = "smc";
	};

	trust_ui_vm_vblk0_ring: trust_ui_vm_vblk0_ring {
		size = <0x4000>;
		gunyah-label = <0x11>;
	};

	trust_ui_vm_vblk1_ring: trust_ui_vm_vblk1_ring {
		size = <0x4000>;
		gunyah-label = <0x10>;
	};

	trust_ui_vm_swiotlb: trust_ui_vm_swiotlb {
		size = <0x100000>;
		gunyah-label = <0x12>;
	};

	trust_ui_vm: qcom,trust_ui_vm {
		vm_name = "trustedvm";
		shared-buffers-size = <0x108000>;
		shared-buffers = <&trust_ui_vm_vblk0_ring
				&trust_ui_vm_vblk1_ring
				&trust_ui_vm_swiotlb>;
	};

	trust_ui_vm_virt_be0: trust_ui_vm_virt_be0@11 {
		qcom,vm = <&trust_ui_vm>;
		qcom,label = <0x11>;
	};

	trust_ui_vm_virt_be1: trust_ui_vm_virt_be1@10 {
		qcom,vm = <&trust_ui_vm>;
		qcom,label = <0x10>;
	};

	gh-secure-vm-loader@0 {
		compatible = "qcom,gh-secure-vm-loader";
		qcom,pas-id = <28>;
		qcom,vmid = <45>;
		qcom,firmware-name = "trustedvm";
		memory-region = <&trust_ui_vm_mem &vm_comm_mem>;
		virtio-backends = <&trust_ui_vm_virt_be0 &trust_ui_vm_virt_be1>;
	};

	oem_vm_vblk0_ring: oem_vm_vblk0_ring {
		size = <0x4000>;
		gunyah-label = <0x13>;
	};

	oem_vm_swiotlb: oem_vm_swiotlb {
		size = <0x100000>;
		gunyah-label = <0x14>;
	};

	oem_vm: qcom,oem_vm {
		vm_name = "oemvm";
		shared-buffers-size = <0x104000>;
		shared-buffers = <&oem_vm_vblk0_ring &oem_vm_swiotlb>;
	};

	oem_vm_virt_be0: oem_vm_virt_be0@13 {
		qcom,vm = <&oem_vm>;
		qcom,label = <0x13>;
	};

	gh-secure-vm-loader@1 {
		compatible = "qcom,gh-secure-vm-loader";
		qcom,pas-id = <34>;
		qcom,vmid = <49>;
		qcom,firmware-name = "oemvm";
		memory-region = <&oem_vm_mem &vm_comm_mem>;
		virtio-backends = <&oem_vm_virt_be0>;
	};
};

&reserved_memory {
	#address-cells = <2>;
	#size-cells = <2>;
	ranges;

	gunyah_hyp_mem: gunyah_hyp_region@80000000 {
		no-map;
		reg = <0x0 0x80000000 0x0 0xe00000>;
	};

	cpusys_vm_mem: cpusys_vm_region@80e00000 {
		no-map;
		reg = <0x0 0x80e00000 0x0 0x400000>;
	};

	/* merge of cpucp_mem and pdp_mem */
	cpucp_pdp_mem: cpucp_pdp_region@81200000 {
		no-map;
		reg = <0x0 0x81200000 0x0 0x200000>;
	};

	/*
	 * hyp_tags_mem is dynamically removed from the RAM
	 * partition tables before boot occurs. Size of region
	 * varies.
	 */

	xbl_dtlog_mem: xbl_dtlog_region@81a00000 {
		no-map;
		reg = <0x0 0x81a00000 0x0 0x40000>;
	};

	aop_image_mem: aop_image_region@81c00000 {
		no-map;
		reg = <0x0 0x81c00000 0x0 0x60000>;
	};

	aop_cmd_db_mem: aop_cmd_db_region@81c60000 {
		compatible = "qcom,cmd-db";
		no-map;
		reg = <0x0 0x81c60000 0x0 0x20000>;
	};

	/* merged aop_config, tme_crash_dump, tme_log and uefi_log regions */
	aop_tme_uefi_merged_mem: aop_tme_uefi_merged_region@81c80000 {
		no-map;
		reg = <0x0 0x81c80000 0x0 0x74000>;
	};

	/* secdata region can be reused by apps */

	smem_mem: smem_region@81d00000 {
		compatible = "qcom,smem";
		reg = <0x0 0x81d00000 0x0 0x200000>;
		hwlocks = <&tcsr_mutex 3>;
		no-map;
	};

	pdp_ns_shared_mem: pdp_ns_shared_region@81f00000 {
		no-map;
		reg = <0x0 0x81f00000 0x0 0x100000>;
	};

	cpucp_scandump_mem: cpucp_scandump_region@82000000 {
		no-map;
		reg = <0x0 0x82000000 0x0 0x380000>;
	};

	adsp_mhi_mem: adsp_mhi_region@82380000 {
		no-map;
		reg = <0x0 0x82380000 0x0 0x20000>;
	};

	soccp_sdi_mem: soccp_sdi_region@823a0000 {
		no-map;
		reg = <0x0 0x823a0000 0x0 0x40000>;
	};

	pmic_minii_dump_mem: pmic_minii_dump_region@823e0000 {
		no-map;
		reg = <0x0 0x823e0000 0x0 0x80000>;
	};

	pvm_fw_mem: pvm_fw_region@824a0000 {
		no-map;
		reg = <0x0 0x824a0000 0x0 0x100000>;
	};

	/* hyp_mem_database_mem is removed by HYP in the RAM partition table */

	global_sync_mem: global_sync_region@82600000 {
		no-map;
		reg = <0x0 0x82600000 0x0 0x100000>;
	};

	tz_stat_mem: tz_stat_region@82700000 {
		no-map;
		reg = <0x0 0x82700000 0x0 0x100000>;
	};

	qdss_apps_mem: qdss_apps_region@82800000 {
		no-map;
		reg = <0x0 0x82800000 0x0 0x2000000>;
	};

	dsm_partition_1_mem: dsm_partition_1_region@84a00000 {
		no-map;
		reg = <0x0 0x84a00000 0x0 0x4900000>;
	};

	dsm_partition_2_mem: dsm_partition_2_region@89300000 {
		no-map;
		reg = <0x0 0x89300000 0x0 0xa80000>;
	};

	mpss_mem: mpss_region@89e00000 {
		no-map;
		reg = <0x0 0x89e00000 0x0 0x11200000>;
	};

	q6_mpss_dtb_mem: q6_mpss_dtb_region@9b000000 {
		no-map;
		reg = <0x0 0x9b000000 0x0 0x80000>;
	};

	ipa_fw_mem: ipa_fw_region@9b080000 {
		no-map;
		reg = <0x0 0x9b080000 0x0 0x10000>;
	};

	ipa_gsi_mem: ipa_gsi_region@9b090000 {
		no-map;
		reg = <0x0 0x9b090000 0x0 0xa000>;
	};

	gpu_microcode_mem: gpu_microcode_region@9b09a000 {
		no-map;
		reg = <0x0 0x9b09a000 0x0 0x2000>;
	};

	spss_region_mem: spss_region_region@9b0a0000 {
		no-map;
		reg = <0x0 0x9b0a0000 0x0 0x1e0000>;
	};

	/* First part of the "SPU secure shared memory" region */
	spu_tz_shared_mem: spu_secure_shared_memory_region@9b280000 {
		no-map;
		reg = <0x0 0x9b280000 0x0 0x40000>;
	};

	/* Second part of the "SPU secure shared memory" region */
	spu_modem_shared_mem: spu_secure_shared_memory_region@9b2c0000 {
		no-map;
		reg = <0x0 0x9b2c0000 0x0 0x40000>;
	};

	camera_mem: camera_region@9b300000 {
		no-map;
		reg = <0x0 0x9b300000 0x0 0x800000>;
	};

	camera_2_mem: camera_2_region@9bb00000 {
		no-map;
		reg = <0x0 0x9bb00000 0x0 0x800000>;
	};

	video_mem: video_region@9c300000 {
		no-map;
		reg = <0x0 0x9c300000 0x0 0x800000>;
	};

	cvp_mem: cvp_region@9cb00000 {
		no-map;
		reg = <0x0 0x9cb00000 0x0 0x700000>;
	};

	cdsp_mem: cdsp_region@9d200000 {
		no-map;
		reg = <0x0 0x9d200000 0x0 0x2000000>;
	};

	q6_cdsp_dtb_mem: q6_cdsp_dtb_region@9f200000 {
		no-map;
		reg = <0x0 0x9f200000 0x0 0x80000>;
	};

	q6_adsp_dtb_mem: q6_adsp_dtb_region@9f280000 {
		no-map;
		reg = <0x0 0x9f280000 0x0 0x80000>;
	};

	adspslpi_mem: adspslpi_region@9f300000 {
		no-map;
		reg = <0x0 0x9f300000 0x0 0x4080000>;
	};

	soccp_mem: soccp_region@a3380000 {
		no-map;
		reg = <0x0 0xa3380000 0x0 0x180000>;
	};

	soccp_dtb_mem: soccp_dtb_region@a3500000 {
		no-map;
		reg = <0x0 0xa3500000 0x0 0x40000>;
	};

	dcp_dtb_mem: dcp_dtb_region@a3540000 {
		no-map;
		reg = <0x0 0xa3540000 0x0 0x40000>;
	};

	dcp_mem: dcp_region@a3580000 {
		no-map;
		reg = <0x0 0xa3580000 0x0 0x600000>;
	};

	/* UEFI region at 0xa7000000 is reclaimed by Linux */

	/* Linux kernel image is loaded at 0xa8000000 */

	xbl_ramdump_mem: xbl_ramdump_region@b8000000 {
		no-map;
		reg = <0x0 0xb8000000 0x0 0x1c0000>;
	};

	/* merged tz_reserved, xbl_sc, and qtee regions */
	tz_merged_mem: tz_merged_region@d8000000 {
		no-map;
		reg = <0x0 0xd8000000 0x0 0x600000>;
	};

	/* vm_kernel_memoem_configurable_mem was split into trust_ui_vm_mem & oem_vm_mem below */
	trust_ui_vm_mem: trust_ui_vm_region@f3800000 {
		compatible = "shared-dma-pool";
		reg = <0x0 0xf3800000 0x0 0x4400000>;
		reusable;
		alignment = <0x0 0x400000>;
	};

	oem_vm_mem: oem_vm_region@f7c00000 {
		compatible = "shared-dma-pool";
		reg = <0x0 0xf7c00000 0x0 0x4c00000>;
		reusable;
		alignment = <0x0 0x400000>;
	};

	vm_comm_mem: vm_comm_mem_region {
		compatible = "shared-dma-pool";
		alloc-ranges = <0x0 0x00000000 0x0 0xffffffff>;
		reusable;
		alignment = <0x0 0x400000>;
		size = <0x0 0x800000>;
	};

	llcc_lpi_mem: llcc_lpi_region@ff800000 {
		no-map;
		reg = <0x0 0xff800000 0x0 0x800000>;
	};

	/* cdsp eva shared memory */
	cdsp_eva_mem: cdsp_eva_region {
		compatible = "shared-dma-pool";
		alloc-ranges = <0x0 0x00000000 0x0 0xffffffff>;
		reusable;
		alignment = <0x0 0x400000>;
		size = <0x0 0x400000>;
	};

	/*
	 * 6Mb for dma_atomic_pool_init()
	 * 8Mb for kgsl snapshot
	 * 4MB for sharedmem-uio
	 * 13Mb for "qcom,memshare" device
	 * 4.5Mb for minidump_memory
	 * 0.5Mb spare.
	 */
	system_cma: linux,cma {
		compatible = "shared-dma-pool";
		alloc-ranges = <0x0 0x00000000 0x0 0xffffffff>;
		reusable;
		alignment = <0x0 0x400000>;
		size = <0x0 0x2400000>;
		linux,cma-default;
	};
};

#include "canoe-dma-heaps.dtsi"
#include "canoe-pinctrl.dtsi"
#include "canoe-regulators.dtsi"
#include "canoe-qupv3.dtsi"
#include "canoe-usb.dtsi"
#include "msm-arm-smmu-canoe.dtsi"

&qupv3_se7_2uart {
	status = "ok";
};

#include "ipcc-test-canoe.dtsi"
/delete-node/ &ipcc_self_ping_adsp;
/delete-node/ &ipcc_self_ping_cdsp;
/delete-node/ &ipcc_self_ping_slpi;
